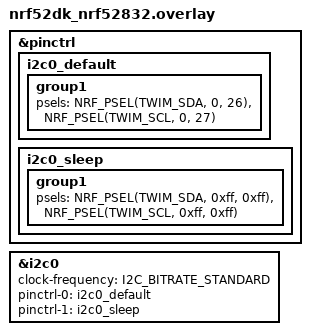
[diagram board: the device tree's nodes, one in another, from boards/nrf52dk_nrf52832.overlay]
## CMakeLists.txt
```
#
# Copyright (c) 2019 Nordic Semiconductor
#
# SPDX-License-Identifier: LicenseRef-Nordic-5-Clause
#

cmake_minimum_required(VERSION 3.20.0)
# set(BOARD nrf52832_custom)

find_package(Zephyr REQUIRED HINTS $ENV{ZEPHYR_BASE})
project(TMP117_fan_trigger)

# NORDIC SDK APP START
target_sources(app PRIVATE
  src/main.c
)
# NORDIC SDK APP END
```

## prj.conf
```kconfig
# I2C + logging
CONFIG_I2C=y
CONFIG_LOG=y
CONFIG_LOG_DEFAULT_LEVEL=3
CONFIG_PRINTK=y

# Console (pick one)
CONFIG_USE_SEGGER_RTT=y
CONFIG_RTT_CONSOLE=y
CONFIG_UART_CONSOLE=y

# Bluetooth (Zephyr NUS)
CONFIG_BT=y
CONFIG_BT_PERIPHERAL=y
CONFIG_BT_EXT_ADV=y
CONFIG_BT_MAX_CONN=1
CONFIG_BT_ZEPHYR_NUS=y
CONFIG_BT_DEVICE_NAME="BLE_Alert"
CONFIG_BT_SMP=n
```

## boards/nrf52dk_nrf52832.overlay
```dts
&pinctrl {
    i2c0_default: i2c0_default {
        group1 {
            psels = <NRF_PSEL(TWIM_SDA, 0, 26)>,
                    <NRF_PSEL(TWIM_SCL, 0, 27)>;
        };
    };

    i2c0_sleep: i2c0_sleep {
        group1 {
            psels = <NRF_PSEL(TWIM_SDA, 0xff, 0xff)>,
                    <NRF_PSEL(TWIM_SCL, 0xff, 0xff)>;
        };
    };
};

&i2c0 {
    status = "okay";
    clock-frequency = <I2C_BITRATE_STANDARD>;
    pinctrl-0 = <&i2c0_default>;
    pinctrl-1 = <&i2c0_sleep>;
    pinctrl-names = "default", "sleep";
};
```

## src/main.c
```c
#include <zephyr/kernel.h>
#include <zephyr/device.h>
#include <zephyr/devicetree.h>
#include <zephyr/drivers/i2c.h>
#include <zephyr/bluetooth/bluetooth.h>
#include <zephyr/bluetooth/hci.h>
#include <zephyr/bluetooth/services/nus.h>
#include <zephyr/sys/printk.h>
#include <string.h>
#include <stdio.h>
#include "TMP117.h"

/* I2C binding */
#define I2C_NODE DT_NODELABEL(i2c0)
static const struct device *i2c_dev = DEVICE_DT_GET(I2C_NODE);

/* BLE */
static struct bt_conn *current_conn;
static struct bt_le_ext_adv *adv;

static void nus_rx_cb(struct bt_conn *conn, const void *data, uint16_t len, void *ctx)
{
    ARG_UNUSED(conn); ARG_UNUSED(ctx);
    printk("NUS RX: %.*s\n", len, (const char *)data);
}
static struct bt_nus_cb nus_cb = { .received = nus_rx_cb };

static void on_connected(struct bt_conn *conn, uint8_t err)
{
    if (err) { printk("BLE connect failed (%u)\n", err); return; }
    current_conn = bt_conn_ref(conn);
    printk("BLE connected\n");
}
static void on_disconnected(struct bt_conn *conn, uint8_t reason)
{
    printk("BLE disconnected (%u)\n", reason);
    if (current_conn) { bt_conn_unref(current_conn); current_conn = NULL; }
    bt_le_ext_adv_start(adv, BT_LE_EXT_ADV_START_DEFAULT);
}
BT_CONN_CB_DEFINE(conn_cbs) = { .connected=on_connected, .disconnected=on_disconnected };

static int start_advertising(void)
{
    const struct bt_le_adv_param params =
        BT_LE_ADV_PARAM_INIT(BT_LE_ADV_OPT_USE_NAME | BT_LE_ADV_OPT_CONNECTABLE,
                             BT_GAP_ADV_FAST_INT_MIN_2,
                             BT_GAP_ADV_FAST_INT_MAX_2,
                             NULL);
    int err = bt_le_ext_adv_create(&params, NULL, &adv);
    if (err) return err;
    return bt_le_ext_adv_start(adv, BT_LE_EXT_ADV_START_DEFAULT);
}
static void bt_ready(int err)
{
    if (err) { printk("bt_ready err=%d\n", err); return; }
    bt_nus_cb_register(&nus_cb, NULL);
    start_advertising();
}

/* ===== Application ===== */
int main(void)
{
    printk("TMP117 dual-sensor BLE Alert demo\n");

    if (!device_is_ready(i2c_dev)) {
        printk("I2C device not ready\n");
        return 0;
    }

    /* Init BLE */
    bt_enable(bt_ready);

    /* Init both TMP117s */
    tmp117_init(i2c_dev, TMP117_ADDR_48);
    tmp117_init(i2c_dev, TMP117_ADDR_49);

    while (1) {
        int tA=0, tB=0, avg=0;
        int eA = tmp117_read_c(i2c_dev, TMP117_ADDR_48, &tA);
        int eB = tmp117_read_c(i2c_dev, TMP117_ADDR_49, &tB);

        if (eA==0 && eB==0) {
            avg = (tA + tB) / 2;
            char msg[64];
            snprintf(msg, sizeof msg,
                     "Avg=%d.%02d C %s\n",
                     avg/100, avg%100,
                     (avg > 2600) ? "PWM_ON" : "PWM_OFF");

            printk("%s", msg);
            if (current_conn) {
                bt_nus_send(current_conn, msg, strlen(msg));
            }
        } else {
            printk("Sensor read error: %d %d\n", eA, eB);
        }
        k_sleep(K_SECONDS(1));
    }
}
```

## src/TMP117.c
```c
#include "TMP117.h"
#include <zephyr/kernel.h>
#include <zephyr/logging/log.h>

LOG_MODULE_REGISTER(tmp117, LOG_LEVEL_INF);

/* Write a 16-bit value */
static int tmp117_write16(const struct device *i2c, uint8_t addr, uint8_t reg, uint16_t val)
{
    uint8_t buf[3] = { reg, (uint8_t)(val >> 8), (uint8_t)(val & 0xFF) };
    return i2c_write(i2c, buf, sizeof(buf), addr);
}

/* Read a 16-bit value */
static int tmp117_read16(const struct device *i2c, uint8_t addr, uint8_t reg, uint16_t *val)
{
    uint8_t buf[2];
    int ret = i2c_write_read(i2c, addr, &reg, 1, buf, 2);
    if (ret) return ret;
    *val = ((uint16_t)buf[0] << 8) | buf[1];
    return 0;
}

/* Initialize TMP117: verify ID and set config */
int tmp117_init(const struct device *i2c, uint8_t addr)
{
    uint16_t id;
    int ret = tmp117_read16(i2c, addr, TMP117_REG_ID, &id);
    if (ret) return ret;

    if (id != 0x0117) {
        LOG_ERR("TMP117 at 0x%02X not found (ID=0x%04X)", addr, id);
        return -ENODEV;
    }
    LOG_INF("TMP117 detected at 0x%02X", addr);

    /* Example config: continuous conversion, average=8, alert=DRDY */
    ret = tmp117_write16(i2c, addr, TMP117_REG_CONFIG, 0x023C);
    if (ret) {
        LOG_ERR("Config write failed (0x%02X)", addr);
        return ret;
    }
    return 0;
}

/* Read temperature in °C*100 (integer) */
int tmp117_read_c(const struct device *i2c, uint8_t addr, int *c_x100)
{
    uint16_t raw;
    int ret = tmp117_read16(i2c, addr, TMP117_REG_TEMP, &raw);
    if (ret) return ret;

    int16_t sraw = (int16_t)raw;
    /* TMP117 LSB = 7.8125 m°C = 0.0078125 °C */
    int32_t temp_cx100 = (sraw * 78125) / 1000;  /* scaled to °C*100 */
    *c_x100 = (int)temp_cx100;
    return 0;
}
```

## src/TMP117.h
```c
#ifndef TMP117_H_
#define TMP117_H_

#include <zephyr/device.h>
#include <zephyr/drivers/i2c.h>
#include <stdint.h>

/* TMP117 register map */
#define TMP117_REG_TEMP    0x00
#define TMP117_REG_CONFIG  0x01
#define TMP117_REG_ID      0x0F

/* TMP117 addresses */
#define TMP117_ADDR_48     0x48
#define TMP117_ADDR_49     0x49

int tmp117_init(const struct device *i2c_dev, uint8_t addr);
int tmp117_read_c(const struct device *i2c_dev, uint8_t addr, int *c_x100);

#endif /* TMP117_H_ */
```
